# apollo2 register map
Vendor: Ambiq Micro, Inc.; Series: Apollo; File version: 1.0
Ultra-Low power ARM Cortex-M4 MCU from Ambiq Micro
CPU: CM4 r1p0, little endian, MPU, FPU, 3 interrupt priority bits
Registers are 32-bit, read-write, reset 0x0 unless marked. A register's access mark holds for its fields unless they carry their own. Offsets are from the block's base; lines under a group give offsets from that group; [hi:lo] are bit positions; {n}, {i} and the like mark numbered series; 'fields as' and 'values as' point back to an identical list; <NAME> marks a mode.

## Memory map
0x40000000 RSTGEN size 0x210 — MCU Reset Generator
0x40004000 CLKGEN size 0x110 — Clock Generator
0x40004040 RTC size 0xD0 — Real Time Clock
0x40008000 CTIMER size 0x310 — Counter/Timer
0x4000C000 VCOMP size 0x210 — Voltage Comparator
0x40010000 GPIO size 0x220 — General Purpose IO
0x40018000 CACHECTRL size 0x240 — Flash Cache Controller
0x4001C000 UART0 size 0x48 — Serial UART
0x4001D000 UART1 size 0x48
0x40020000 MCUCTRL size 0x34C — MCU Miscellaneous Control Logic
0x40021000 PWRCTRL size 0x24 — PWR Controller Register Bank
0x40024000 WDT size 0x210 — Watchdog Timer
0x50000000 IOSLAVE size 0x220 — I2C/SPI Slave
0x50004000 IOMSTR0 size 0x308 — I2C/SPI Master
0x50005000 IOMSTR1 size 0x308
0x50006000 IOMSTR2 size 0x308
0x50007000 IOMSTR3 size 0x308
0x50008000 IOMSTR4 size 0x308
0x50009000 IOMSTR5 size 0x308
0x50010000 ADC size 0x210 — Analog Digital Converter Control
0x50011000 PDM size 0x210 — PDM Audio

## Interrupts
0 BROWNOUT (MCUCTRL)
1 WDT
2 CLKGEN_RTC (CLKGEN)
3 VCOMP
4 IOSLAVE
5 IOSLAVEACC (IOSLAVE)
6 IOMSTR0
7 IOMSTR1
8 IOMSTR2
9 IOMSTR3
10 IOMSTR4
11 IOMSTR5
12 GPIO
13 CTIMER
14 UART0
15 UART1
16 ADC
17 PDM
18 STIMER (CTIMER)
{n+19} STIMER_CMPR{n} (CTIMER) (n=0..7)

## PDM — PDM Audio
Base 0x50011000
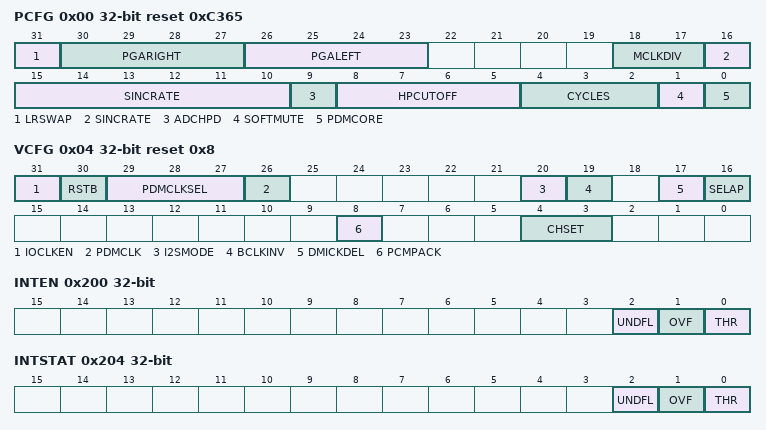
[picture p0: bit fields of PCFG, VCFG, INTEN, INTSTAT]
0x00 PCFG reset 0xC365 — PDM Configuration Register
  [31] LRSWAP — Left/right channel swap.
    1=EN (Swap left and right channels (FIFO Read RIGHT_LEFT).); 0=NOSWAP (No channel swapping (IFO Read LEFT_RIGHT).)
  [30:27] PGARIGHT — Right channel PGA gain.
    15=M15DB (-1.5 db gain.); 14=M300DB (-3.0 db gain.); 13=M45DB (-4.5 db gain.); 12=M60DB (-6.0 db gain.); 11=M75DB (-7.5 db gain.); 10=M90DB (-9.0 db gain.); 9=M105DB (-10.5 db gain.); 8=M120DB (-12.0 db gain.); 7=P105DB (10.5 db gain.); 6=P90DB (9.0 db gain.); 5=P75DB (7.5 db gain.); 4=P60DB (6.0 db gain.); 3=P45DB (4.5 db gain.); 2=P30DB (3.0 db gain.); 1=P15DB (1.5 db gain.); 0=0DB (0.0 db gain.)
  [26:23] PGALEFT — Left channel PGA gain.
    values as PGARIGHT
  [18:17] MCLKDIV — PDM_CLK frequency divisor.
    {v}=MCKDIV{v+1} (Divide input clock by {v+1}) (v=0..3)
  [16:10] SINCRATE — SINC decimation rate.
  [9] ADCHPD — High pass filter disable.
    0=EN (Enable high pass filter.); 1=DIS (Disable high pass filter.)
  [8:5] HPCUTOFF — High pass filter coefficients.
  [4:2] CYCLES — Number of clocks during gain-setting changes.
  [1] SOFTMUTE — Soft mute control.
    1=EN (Enable Soft Mute.); 0=DIS (Disable Soft Mute.)
  [0] PDMCORE — Data Streaming Control.
    1=EN (Enable Data Streaming.); 0=DIS (Disable Data Streaming.)
0x04 VCFG reset 0x8 — Voice Configuration Register
  [31] IOCLKEN — Enable the IO clock.
    0=DIS (Disable FIFO read.); 1=EN (Enable FIFO read.)
  [30] RSTB — Reset the IP core.
    0=RESET (Reset the core.); 1=NORM (Enable the core.)
  [29:27] PDMCLKSEL — Select the PDM input clock.
    0=DISABLE (Static value.); 1=12MHz (PDM clock is 12 MHz.); 2=6MHz (PDM clock is 6 MHz.); 3=3MHz (PDM clock is 3 MHz.); 4=1_5MHz (PDM clock is 1.5 MHz.); 5=750KHz (PDM clock is 750 KHz.); 6=375KHz (PDM clock is 375 KHz.); 7=187KHz (PDM clock is 187.5 KHz.)
  [26] PDMCLK — Enable the serial clock.
    0=DIS (Disable serial clock.); 1=EN (Enable serial clock.)
  [20] I2SMODE — I2S interface enable.
    0=DIS (Disable I2S interface.); 1=EN (Enable I2S interface.)
  [19] BCLKINV — I2S BCLK input inversion.
    0=INV (BCLK inverted.); 1=NORM (BCLK not inverted.)
  [17] DMICKDEL — PDM clock sampling delay.
    0=0CYC (No delay.); 1=1CYC (1 cycle delay.)
  [16] SELAP — Select PDM input clock source.
    1=I2S (Clock source from I2S BCLK.); 0=INTERNAL (Clock source from internal clock generator.)
  [8] PCMPACK — PCM data packing enable.
    0=DIS (Disable PCM packing.); 1=EN (Enable PCM packing.)
  [4:3] CHSET — Set PCM channels.
    0=DIS (Channel disabled.); 1=LEFT (Mono left channel.); 2=RIGHT (Mono right channel.); 3=STEREO (Stereo channels.)
0x08 FR — Voice Status Register
  [8:0] FIFOCNT — Valid 32-bit entries currently in the FIFO.
0x0C FRD — FIFO Read
  [31:0] FIFOREAD — FIFO read data.
0x10 FLUSH — FIFO Flush
  [0] FIFOFLUSH
0x14 FTHR reset 0xC0 — FIFO Threshold
  [7:0] FIFOTHR — FIFO interrupt threshold.
0x200 INTEN — IO Master Interrupts: Enable
  [2] UNDFL — This is the FIFO underflow interrupt.
  [1] OVF — This is the FIFO overflow interrupt.
  [0] THR — This is the FIFO threshold interrupt.
0x204 INTSTAT — IO Master Interrupts: Status
  fields as INTEN
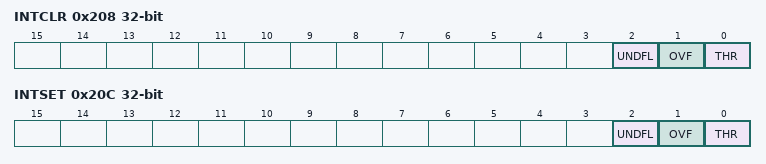
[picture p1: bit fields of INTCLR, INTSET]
0x208 INTCLR — IO Master Interrupts: Clear
  fields as INTEN
0x20C INTSET — IO Master Interrupts: Set
  fields as INTEN

## Licence text in the file
Copyright (c) 2020, Ambiq Micro. All rights reserved. . Redistribution and use in source and binary forms, with or without modification, are permitted provided that the following conditions are met: . 1. Redistributions of source code must retain the above copyright notice, this list of conditions and the following disclaimer. . 2. Redistributions in binary form must reproduce the above copyright notice, this list of conditions and the following disclaimer in the documentation and/or other materials provided with the distribution. . 3. Neither the name of the copyright holder nor the names of its contributors may be used to endorse or promote products derived from this software without specific prior written permission. . Third party software included in this distribution is subject to the additional license terms as defined in the /docs/licenses directory. . THIS SOFTWARE IS PROVIDED BY THE COPYRIGHT HOLDERS AND CONTRIBUTORS "AS IS" AND ANY EXPRESS OR IMPLIED WARRANTIES, INCLUDING, BUT NOT LIMITED TO, THE. IMPLIED WARRANTIES OF MERCHANTABILITY AND FITNESS FOR A PARTICULAR PURPOSE. ARE DISCLAIMED. IN NO EVENT SHALL THE COPYRIGHT HOLDER OR CONTRIBUTORS BE. LIABLE FOR ANY DIRECT, INDIRECT, INCIDENTAL, SPECIAL, EXEMPLARY, OR. CONSEQUENTIAL DAMAGES (INCLUDING, BUT NOT LIMITED TO, PROCUREMENT OF. SUBSTITUTE GOODS OR SERVICES; LOSS OF USE, DATA, OR PROFITS; OR BUSINESS. INTERRUPTION) HOWEVER CAUSED AND ON ANY THEORY OF LIABILITY, WHETHER IN. CONTRACT, STRICT LIABILITY, OR TORT (INCLUDING NEGLIGENCE OR OTHERWISE). ARISING IN ANY WAY OUT OF THE USE OF THIS SOFTWARE, EVEN IF ADVISED OF THE. POSSIBILITY OF SUCH DAMAGE.

## Notices in the file
Copyright (C) 2012-2014 ARM Limited. All rights reserved.
Purpose: System Viewer Description (SVD) Example (Schema Version 1.1)
This is a description of a none-existent and incomplete device
for demonstration purposes only.
- Neither the name of ARM nor the names of its contributors may be used
ARE DISCLAIMED. IN NO EVENT SHALL COPYRIGHT HOLDERS AND CONTRIBUTORS BE
